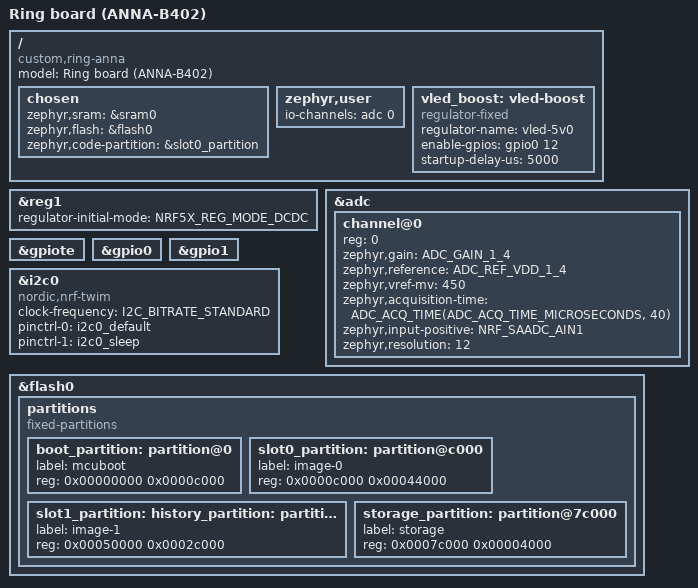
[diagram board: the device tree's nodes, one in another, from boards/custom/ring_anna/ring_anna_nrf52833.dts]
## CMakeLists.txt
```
cmake_minimum_required(VERSION 3.20.0)

find_package(Zephyr REQUIRED HINTS $ENV{ZEPHYR_BASE})
project(ring_ppg)

target_sources(app PRIVATE
	src/main.c
	src/maxm86161.c
	src/hr.c
	src/selftest.c
	src/ble.c
	src/imu.c
	src/wdt.c
	src/steps.c
	src/sleep.c
	src/calories.c
	src/profile.c
	src/hrv.c
	src/spo2.c
	src/history.c
	src/thermo.c
	src/spot.c
	src/ota.c
)

# ota.c includes img_mgmt.h, which pulls in MCUboot's bootutil headers.
# img_mgmt gets their include paths by linking this interface library;
# so does the app.
if(CONFIG_MCUBOOT_IMG_MANAGER)
	target_link_libraries(app PRIVATE MCUBOOT_BOOTUTIL)
endif()
```

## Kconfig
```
# Ring firmware application options.
#
# This file becomes KCONFIG_ROOT for the application (see Zephyr's
# cmake/modules/kconfig.cmake), so it MUST end by sourcing Kconfig.zephyr or
# no Zephyr symbol resolves at all.
#
# Everything bench-only lives here rather than as a #define inside a .c
# file. That is deliberate: the flags used to be scattered across main.c and
# imu.c, and "production" was produced by hand-editing main.c and keeping a
# main.c.bench copy alongside it. Two files that have to be edited in step
# is a bug waiting to happen, and the duplicate rotted immediately.
#
# Now both images come from one tree with no file edits:
#
#   .\build.ps1            production
#   .\build.ps1 -Bench     bench instrumentation

mainmenu "Ring firmware"

menu "Ring firmware"

config RING_BENCH
	bool "Bench instrumentation (NOT for anything worn or shipped)"
	help
	  Master switch for every bench-only instrument in this firmware.

	  These instruments perturb what they measure and defeat the power
	  model, which is fine on a desk with a debugger attached and wrong
	  everywhere else. Off by default so an ordinary build is shippable.

if RING_BENCH

config RING_BENCH_POWER_LED
	bool "Hold the green LED on as a power indicator"
	default y
	help
	  Holds MAXM86161 LED1 solid so "is the board actually running?" is
	  answerable by looking at it rather than by attaching a debugger.
	  Hours went into faults that turned out to be an unpowered board
	  presenting as a dead SWD link.

	  Costs real current and keeps the 5 V boost enabled permanently,
	  so the idle power model does not apply while this is set.

config RING_IMU_WAKE_DIAG
	bool "IMU wake-path diagnostics"
	default y
	help
	  Samples the INT1 pin before reading the latched wake source, which
	  separates "the IMU never fired" from "the IMU fired and the pin did
	  not move". This is what localised the cold joint on U4.

	  It reads latched registers and pulses INT1, so it perturbs the very
	  interrupt path the firmware depends on. Never leave it on outside
	  bring-up.

config RING_GSR_MONITOR
	bool "Live GSR monitor"
	default y
	help
	  Samples GSR in every state and holds GSR_PWR on continuously so the
	  front end stays settled and a meter can reach it.

	  Holding GSR_PWR on defeats duty cycling and keeps the analog front
	  end powered for as long as the board is.

endif # RING_BENCH

config RING_WATCHDOG
	bool "Hardware watchdog"
	default y
	select WATCHDOG
	help
	  Resets the SoC if the main loop stops feeding it. Without this a
	  wedged I2C bus or a hung loop is an unrecoverable brick that only a
	  power cycle clears -- and on a sealed ring, that means waiting for
	  the battery to die.

	  The nRF52833 watchdog CANNOT be stopped once started; only a
	  power-on reset clears it. It is therefore started last, after all
	  initialisation has succeeded.

config RING_WATCHDOG_TIMEOUT_MS
	int "Watchdog timeout (ms)"
	default 10000
	range 1000 100000
	depends on RING_WATCHDOG
	help
	  Must comfortably exceed the longest span between two
	  ring_wdt_feed() calls, because exceeding it reboots a board that
	  is merely slow.

	  THE AUDIT LIVES BESIDE THE FEED CALL IN main.c, and that is the
	  only copy. A duplicate of the numbers used to sit here and went
	  stale immediately: it counted only the k_msleep() delays, missed
	  that a stalled I2C bus costs 500 ms per transaction, and claimed
	  a margin that did not exist. Read main.c rather than trusting a
	  figure quoted here.

config RING_SLEEP_WEAR_CHECK
	bool "Corroborate sleep sessions with a PPG wear check"
	default y
	help
	  Opens a short PPG window every so often while a sleep session is
	  open, purely to read the DC level and answer "is this ring on a
	  hand?". Without it, stillness is the only input the sleep tracker
	  has and a ring left on a nightstand logs a full night -- confirmed
	  behaviour, not a hypothesis.

	  It costs LED current at night, but only where the answer is "no".
	  A worn ring never goes stale -- finding a finger during an ordinary
	  window refreshes the motion timeout -- so it is already measuring
	  every minute and its scheduled windows answer this for free: at
	  most one extra 6 s window per session, and usually none. A ring off
	  a finger DOES go stale three minutes in, and there the check adds
	  roughly 16 windows of 6 s, about 96 s of LED1 per night at ~15.4 mA
	  off the 5 V rail, against the ~12 s that night cost before.

	  That is ~0.41 mAh at 5 V, or ~0.65 mAh referred to a 3.7 V cell at
	  an assumed 85 % boost efficiency, before the AFE's own draw. NOBODY
	  HAS MEASURED THE BATTERY, so what fraction of a night that is
	  remains unknown. The arithmetic and the simulated window counts are
	  in STATUS.md section 5; the far larger pre-existing cost of the
	  duty cycle itself is R13 in the same file.

	  The verdict is reported, never enforced: a session that fails the
	  check is still reported as sleep, and the app decides what to do
	  with it.

	  Set this to n and no window is ever opened to ask the question, so
	  the power model is exactly what it was before this option existed.
	  Sessions then report RING_WEAR_UNKNOWN, except where a window
	  opened for some other reason -- an app-forced measurement, opcode
	  0x03 -- happens to land inside one. That reading is free and is
	  still recorded either way.

config RING_SLEEP_WEAR_CHECK_INTERVAL_MIN
	int "Minutes between sleep wear checks"
	default 30
	range 5 1440
	depends on RING_SLEEP_WEAR_CHECK
	help
	  How long to wait between wear checks within one sleep session. The
	  first check of a session is taken as soon as the session opens, so
	  a verdict of "not worn" -- which needs two negatives -- lands about
	  one interval after onset.

	  Cost scales linearly: halving this doubles the LED time per night.
	  Set it beyond a night's length (say 600) to get exactly one check
	  per session, which is the cheapest useful setting and cannot notice
	  a ring taken off at 2 am.

config RING_SLEEP_WEAR_CHECK_WINDOW_MS
	int "Length of a sleep wear-check window (ms)"
	default 6000
	range 4000 30000
	depends on RING_SLEEP_WEAR_CHECK
	help
	  How long the PPG runs for one wear check. This only has to settle
	  the DC tracker, not acquire a heart rate, so it is far shorter than
	  MEASURE_WINDOW_MS.

	  The floor is the ~4 s settling figure the measurement window is
	  sized around; the 6 s default is that plus margin. Nothing shorter
	  has been tried on hardware, because there is no hardware -- do not
	  lower the floor on the strength of the filter time constant alone.

config RING_HR_CONTINUOUS
	bool "Keep the PPG running continuously (heart-rate test builds only)"
	default n
	help
	  Opens a measurement window at boot and never closes it, so heart
	  rate is computed and notified over the standard Heart Rate Service
	  once a second for as long as the board is up. Nothing has to pair
	  or send an opcode: any HRS client that connects sees live BPM.

	  Exists to test the optical path and the beat detector against a
	  reference on a bench. It ignores the duty cycle, the no-finger
	  timeout and the stillness timeout, so green LED1 and the 5 V boost
	  run the whole time -- never ship it. Built with hr-test.conf into
	  build-hrtest, so it cannot be left where a production image is
	  expected.

config RING_PPG_ON_DEMAND
	bool "Measure only when the app asks -- no automatic windows"
	default n
	help
	  Drops the duty cycle: no scheduled window every minute, no window
	  on a motion wake. Green LED1 and the 5 V boost come on only when
	  the app asks -- PPG streaming (opcode 0x01), which holds a window
	  open for as long as it runs, or measure-now (opcode 0x03), which
	  opens one 25 s window. A connected app can do everything it could
	  before; the ring just never decides to measure on its own.

	  For demos and bench sessions where the ring is carried around all
	  day and should only light up when someone is watching. It also
	  means no heart rate unless an app is connected and asking, so it
	  is not a shipping configuration. Built by .\build.ps1 -Demo with
	  demo.conf, which also turns the sleep wear check off.

config RING_CHARGE_LED
	bool "Hold the red LED on for as long as the charger is attached"
	default n
	help
	  Without this, attaching a charger flashes LED3 red for 3 s and then
	  leaves the optics dark. With it, red stays on until the charger is
	  removed, and the ring then goes back to whatever it was doing --
	  in an HR test build, green heart-rate measurement.

	  It is not free: the indicator holds the 5 V boost up and averages
	  roughly 2 mA of LED current (~3 mA at the cell) against a 20 mA
	  charge current, so a charge takes on the order of 15 % longer.
	  Off by default for that reason; hr-test.conf turns it on.

config RING_MEASURE_PERIOD_S
	int "Seconds between automatic measurement windows"
	default 60
	range 15 3600
	help
	  Each window lights green LED1 for 25 s, and the LED plus the 5 V
	  boost are the dominant draw on this board. 60 s is 25 % duty;
	  daily.conf uses 600 s (2.5 %) so a ring worn all day lasts the
	  day. The app can still change it at runtime with opcode 0x04.

config RING_HISTORY_EPOCH_S
	int "Seconds summarised by each on-ring history record"
	default 300
	range 60 3600
	help
	  The ring writes one 32-byte summary to flash every epoch -- heart
	  rate (mean, min, max), RMSSD, spot readings, steps, temperature,
	  motion, hot flashes, battery and worn/charging/asleep/workout flags
	  -- whether or not a phone is connected, and the app downloads them
	  later (control opcode 0x0E). See src/history.h and
	  APP_INTEGRATION.md section 16.

	  The partition holds 5,504 records, so capacity is this times
	  5,504: 19 days at the default 300 s, 3.8 days at 60 s. Shorter
	  epochs also wear the flash faster, though even 60 s cycles each
	  page only about twice a week.

config RING_PPG_LED_PA
	int "Green LED drive code for heart-rate windows (0.12 mA per LSB)"
	default 255
	range 1 255
	help
	  0xFF (255) is ~30.6 mA, 0x80 (128) ~15.4 mA, in the 31 mA range.
	  Together with RING_PPG_AVG_LOG2 this sets the LED energy per
	  sample, which dominates the ring's power budget while it measures
	  (POWER.md): the MAXM86161 draws ~600 uA from VLED at 100 sps with
	  0xFF and one pulse a sample, and scales with both settings.

	  255 is what every test build ran since v0.6.2. prod.conf sets 128.
	  Opcode 0x10 overrides it at run time in test builds.

config RING_PPG_AVG_LOG2
	int "On-chip averaging for heart-rate windows: 2^n pulses a sample"
	default 2
	range 0 2
	help
	  0, 1, 2 = average 1, 2, 4 pulses; output stays 100 sps. Each step
	  doubles the LED energy. 2 (4x) is what every test build ran since
	  v0.6.2; prod.conf sets 1 (2x).

	  Why production is not at 4x: on 2026-10-08's 30 s recordings, the
	  cheapest setting (15 mA, no averaging) scored as well as 31 mA with
	  4x once the detector despikes -- at an eighth of the LED energy --
	  but 30 s per setting cannot separate them. Settle it with
	  tools/ppg_sweep.py --ab against a WHOOP.

config RING_IMU_LOW_POWER
	bool "Run the accelerometer in low-power mode at 60 Hz"
	default n
	help
	  The accelerometer runs all day -- wake-on-motion and the step
	  counter need it -- and every build so far ran it in high-performance
	  mode at 120 Hz: ~190 uA by the LSM6DSV datasheet, several mAh a day
	  on its own. Low-power mode with 4-sample averaging at 60 Hz is ~20
	  uA, with somewhat more noise -- a few mg, against the ~80-100 mg
	  swings that wake the ring and count a step.

	  NOT YET VERIFIED ON HARDWARE. The register value comes from ST's
	  LSM6DSV16BX driver, but nobody has checked that wake-on-motion still
	  fires and steps still count in this mode on the ring. Off in the test
	  builds; prod.conf turns it on, and the first prod flash must confirm
	  both (ROADMAP.md).

config RING_DIAG_OPCODES
	bool "Accept diagnostic control opcodes 0x10 (PPG tune) and 0x11 (TX power)"
	default y
	help
	  Lets tools/ppg_sweep.py change the PPG front end and the radio's
	  transmit power over BLE without a reflash. On for every test build,
	  as it was in v0.6.2.

	  Off in production (prod.conf): they are tuning instruments, not
	  settings, and 0x11 is suspected of one reboot (2026-10-08) that was
	  never cleared. With this off both opcodes are refused with ATT 0x13
	  like any unknown opcode.

config RING_GSR_STATUS
	bool "Sample GSR every 30 s for the status packet"
	default y
	help
	  Powers the GSR front end and waits its 800 ms settle every 30 s to
	  fill gsr_mv in the Status characteristic. On for every test build,
	  as it was in v0.6.2.

	  Off in production (prod.conf), for two reasons learned in testing:
	  the front end cannot resolve skin conductance on this board (gain
	  about 10x too low, noise larger than the signal), and the 800 ms
	  settle blocks the main loop, so the step counter misses a stride
	  every 30 s of walking. gsr_mv then reads -1 ("not measured"). The
	  raw GSR stream (opcode 0x08) still works for diagnostics.

config RING_ADV_SLOW_AFTER_S
	int "Seconds of fast advertising before slowing to ~1 s (0 = never)"
	default 0
	range 0 3600
	help
	  The ring advertises every 30-60 ms so a phone finds it at once. Kept
	  up all day while nothing is connected, that is roughly 20 radio
	  events a second, likely several mAh a day at +8 dBm -- a large share
	  of a battery this small. With this set, advertising
	  drops to 1-1.2 s once it has run fast for this long after boot or
	  a disconnect. A phone still finds the ring within about a second;
	  it just stops paying for instant discovery nobody is waiting on.

	  0 (the default) keeps the fast advertising every test build had.
	  prod.conf sets 30.

config RING_CONN_PARAM_MGMT
	bool "Ask the central for an idle or fast connection interval"
	default n
	help
	  Without this the ring keeps whatever interval the phone or PC
	  chose, typically 15-30 ms, for the whole connection. With it the
	  ring asks for ~100 ms with latency 4 while idle, waking about every
	  half second, and 15-30 ms while a raw stream or a history sync
	  needs the throughput. See ble_service() in ble.c.

	  Off by default, as every test build was. prod.conf turns it on.

config RING_HRS_OPEN
	bool "Leave the standard Heart Rate Service readable without pairing"
	default y
	depends on BT_HRS
	help
	  Heart rate is a biometric, and by default this firmware broadcasts
	  it over the standard Heart Rate Service (0x180D) with no encryption
	  required: anyone in range who connects can read it. That is a
	  deliberate trade, not an oversight.

	  Keep it y and any off-the-shelf HR app -- a watch face, a cycling
	  computer, a generic BLE HRM client -- pairs with nothing and just
	  works, which is the whole point of implementing the SIG service
	  instead of only the custom one. The cost is that resting heart rate
	  leaks to anybody within a few metres.

	  Set it to n and the HRS characteristics require an encrypted link,
	  so only a bonded phone can read heart rate. Generic clients that do
	  not pair will see the service, fail to subscribe, and show nothing.
	  The Ring Service status packet has always been encrypted and carries
	  hr_x10, so a first-party app loses nothing either way.

	  This does not touch the Battery Service, which stays open.

config RING_SPOT_NIGHT_MIN
	int "Minutes between night spot readings (0 = off)"
	default 0
	range 0 720
	help
	  A spot reading is a long green PPG window -- RING_SPOT_WINDOW_S --
	  taken for a clean resting heart rate and RMSSD rather than a quick
	  heart rate. Night readings start 15 min after sleep onset and
	  repeat at this interval while asleep. They are what the app's
	  burnout trend is built on. See src/spot.h.

	  Off by default, as every test build was. prod.conf sets 60. The
	  app can change it at run time (opcode 0x12, RAM only). 1-9 are
	  refused there, and raised to 10 here (spot_init()): back-to-back
	  readings would keep the LED on all night.

config RING_SPOT_DAY_MIN
	int "Minutes between daytime spot readings (0 = off)"
	default 0
	range 0 720
	help
	  Daytime spot readings: awake, worn, and the accelerometer still
	  for 3 minutes, at most once per this interval. The app's stress
	  readings come from these, against the night baseline.

	  Off by default. prod.conf sets 60.

config RING_SPOT_WINDOW_S
	int "Length of a spot reading, seconds"
	default 180
	range 60 600
	help
	  Long enough for the beat detector to prime (~10 s) and then
	  collect well over a hundred consecutive beats at a resting heart
	  rate; the reading's RMSSD is over all of them (hrv_session). Each reading at the default costs about seven
	  25 s heart-rate windows' worth of LED.

config RING_HOT_FLASH_MODE
	int "Hot-flash detection: 0 off, 1 while asleep, 2 always"
	default 0
	range 0 2
	help
	  Watches the ring temperature for the quick rise of a hot flash --
	  see src/thermo.h for the algorithm and its caveats. The
	  temperature itself is logged in every build regardless; this only
	  decides whether events are detected, counted, flagged in the
	  history and followed by a spot reading.

	  Off by default. prod.conf sets 1: night sweats are the case the
	  temperature can see cleanly, a still hand under a duvet. The app
	  can change it (opcode 0x13).

config RING_HOT_FLASH_RISE_C10
	int "Hot-flash onset threshold, tenths of a degree C"
	default 10
	range 3 50
	help
	  How far above its settled baseline the ring temperature has to
	  climb, three quarters of it within 10 minutes. 1.0 C is a
	  starting point, not a fit: the nRF die reads the finger through
	  the ring, attenuated, and nobody has worn this board through a
	  hot flash yet.

# Selecting a choice entry provokes a Kconfig warning, so steer the choice
# instead. This file is KCONFIG_ROOT and sources Kconfig.zephyr at the end,
# so this default is evaluated before the upstream one in
# subsys/bluetooth/services/Kconfig.hrs.
choice BT_HRS_DEFAULT_PERM
	default BT_HRS_DEFAULT_PERM_RW_ENCRYPT if BT_HRS && !RING_HRS_OPEN
endchoice

endmenu

source "Kconfig.zephyr"
```

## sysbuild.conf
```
# Sysbuild: MCUboot in front of the app, for over-the-air updates (OTA.md).
#
# Overwrite-only, because two full image slots do not fit beside the
# history log in 512 kB (see the partitions in the board DTS). That mode
# has no revert: MCUboot checks the update's signature and hash before it
# copies, so a damaged or foreign upload is refused and the old image
# keeps running, but a correctly signed image that is broken in itself
# stays installed. Try every release on an unsealed board first.
SB_CONFIG_BOOTLOADER_MCUBOOT=y
SB_CONFIG_MCUBOOT_MODE_OVERWRITE_ONLY=y

# The update is LZMA2-compressed so it fits the 176 kB secondary slot,
# which is the history partition.
SB_CONFIG_MCUBOOT_COMPRESSED_IMAGE_SUPPORT=y

# ECDSA P-256 with this project's own key, not MCUboot's published
# development key -- anyone holding that one could sign an image this
# ring would accept. keys/ is gitignored: keep a copy of the key
# somewhere safe, because without it no sealed ring can be updated again.
SB_CONFIG_BOOT_SIGNATURE_TYPE_ECDSA_P256=y
SB_CONFIG_BOOT_SIGNATURE_KEY_FILE="\${APP_DIR}/keys/ring-mcuboot-ecdsa-p256.pem"
```

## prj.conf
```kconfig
CONFIG_I2C=y
CONFIG_GPIO=y
CONFIG_REGULATOR=y
CONFIG_REGULATOR_FIXED=y

# There is no UART on this board -- SWD is the only wire out, so the console
# and the log backend both go over SEGGER RTT.
CONFIG_SERIAL=n
CONFIG_UART_CONSOLE=n
CONFIG_USE_SEGGER_RTT=y
CONFIG_RTT_CONSOLE=y
CONFIG_CONSOLE=y

CONFIG_LOG=y
CONFIG_LOG_BACKEND_RTT=y
CONFIG_LOG_BACKEND_UART=n
CONFIG_LOG_BUFFER_SIZE=4096

# The default 1 kB SEGGER RTT up-buffer overflows during boot and silently
# drops log lines -- the IMU init and wake readback landed in the gap. The
# backend drops rather than blocks, so this is invisible except as missing
# timestamps. 8 kB covers the whole boot sequence.
CONFIG_SEGGER_RTT_BUFFER_SIZE_UP=8192

CONFIG_MAIN_STACK_SIZE=2048

# GSR analog front end
CONFIG_ADC=y

# --- Bluetooth: standard Heart Rate Monitor peripheral ---
CONFIG_BT=y
CONFIG_BT_PERIPHERAL=y
CONFIG_BT_DEVICE_NAME="Ring PPG"
CONFIG_BT_DEVICE_APPEARANCE=833
CONFIG_BT_HRS=y
CONFIG_BT_BAS=y
CONFIG_BT_SMP=y
CONFIG_BT_MAX_CONN=1

# No 32.768 kHz crystal on this board, so the controller runs its sleep
# clock from the internal RC (CLOCK_CONTROL_NRF_K32SRC_RC in the board
# defconfig). BLE tolerates the lower accuracy; it just widens receive
# windows slightly and costs a little power.

# Larger ATT MTU so raw PPG streaming is not capped at 4 samples per packet
CONFIG_BT_L2CAP_TX_MTU=247
CONFIG_BT_BUF_ACL_RX_SIZE=251
CONFIG_BT_BUF_ACL_TX_SIZE=251
CONFIG_BT_CTLR_DATA_LENGTH_MAX=251
CONFIG_BT_ATT_PREPARE_COUNT=2
CONFIG_BT_GATT_DYNAMIC_DB=n

# --- Bluetooth: pairing, bonding, encryption --------------------------------
#
# The Ring Service carries biometrics and accepts control opcodes, so every
# one of its attributes now demands an encrypted link (see src/ble.c). The
# ring has no display and no keypad, so the association model is Just Works:
# encrypted, bonded, but no MITM protection. That is the best an IO-less
# peripheral can do, and it is a long way better than the open link this
# replaces.
#
# Bonds have to survive a reboot or every power cycle would force a re-pair,
# so they go through the settings subsystem into a flash partition. NVS is
# the backend: Zephyr 4.4 picks SETTINGS_ZMS if ZMS is on and SETTINGS_NVS
# otherwise, and ZMS targets the RRAM parts (nRF54L), not nRF52 flash.
#
# CONFIG_BT_SMP is already set above.
CONFIG_BT_SETTINGS=y
CONFIG_SETTINGS=y
CONFIG_FLASH=y
CONFIG_FLASH_MAP=y
CONFIG_NVS=y

# Let NVS rebuild a storage partition it cannot make sense of.
#
# nvs_init() walks every sector looking for one that is still open. If they
# all look closed -- which is what stale bytes from an older image, or a
# half-finished erase, present as -- it gives up with -EDEADLK unless this is
# set (subsys/kvss/nvs/nvs.c). -EDEADLK propagates out of settings_load(),
# and since v0.4.1 that is fatal to BLE, so a single garbage sector would
# cost the ring its radio with no way back except an erase over SWD.
#
# With this set NVS flattens the region and starts a fresh instance instead.
# That destroys whatever was there, which for this partition means the bonds
# -- and bonds that cannot be parsed are already lost. Erasing before the
# first flash (see release/README.md) avoids ever needing this; it exists so
# that forgetting to is recoverable in the field rather than on a bench.
CONFIG_NVS_INIT_BAD_MEMORY_REGION=y

# Honour zephyr,code-partition from the board DTS, so the linker knows the
# image must stop short of the settings partition. Without this the chosen
# node is inert and a big enough image would silently overlap the bonds.
CONFIG_USE_DT_CODE_PARTITION=y

# --- Device Information Service ---------------------------------------------
#
# So a phone can tell which firmware it is talking to without a debugger.
# The revision string is also logged at boot from ble_start().
CONFIG_BT_DIS=y
CONFIG_BT_DIS_FW_REV=y
CONFIG_BT_DIS_FW_REV_STR="0.9.0"
CONFIG_BT_DIS_MANUF_NAME_STR="Ring project"
CONFIG_BT_DIS_MODEL_NUMBER_STR="Ring ANNA-B402"

# --- survivability ---------------------------------------------------------
#
# A fatal error (bus fault, stack overflow, failed assert) used to spin
# forever in k_fatal_halt: a dead ring that only a power cycle cleared, and
# on a sealed board that means waiting for the battery to run down. Reboot
# instead. Zephyr's z_fatal_error() calls LOG_PANIC() first, so the fault
# dump is flushed synchronously over RTT before the reset lands.
CONFIG_RESET_ON_FATAL_ERROR=y
CONFIG_REBOOT=y

# Reset cause survives the reset and is read back at boot -- the only way to
# tell a watchdog reset from someone plugging in a charger. See main.c.
CONFIG_HWINFO=y

# Stack overflow is caught by the MPU guard, which the board defconfig
# already enables (CONFIG_ARM_MPU + CONFIG_HW_STACK_PROTECTION). With the
# MPU doing it, CONFIG_STACK_SENTINEL would only add a slower, weaker second
# check, so it is deliberately left off.

# --- radio power at run time ------------------------------------------------
#
# Lets control opcode 0x11 change the TX power of a live connection through
# the controller's vendor HCI command. Exists to answer one question with a
# sweep rather than a reflash: do the PPG glitches follow the radio? The
# default level is still whatever CONFIG_BT_CTLR_TX_PWR_* says.
CONFIG_BT_CTLR_TX_PWR_DYNAMIC_CONTROL=y

# --- over-the-air updates ---------------------------------------------------
#
# MCUboot sits in front of the app (sysbuild.conf) and the SMP server below
# takes a signed, compressed image over BLE into slot 1 -- which is the
# history partition, so src/ota.c stops the log while an upload runs. The
# phone side is Nordic's nRF Connect Device Manager library (or
# tools/ota_update.py). See OTA.md.
CONFIG_MCUMGR=y
CONFIG_ZCBOR=y
CONFIG_CRC=y
CONFIG_STREAM_FLASH=y
CONFIG_IMG_MANAGER=y
CONFIG_MCUBOOT_IMG_MANAGER=y

# The version MCUboot and the phone see in the image header. Keep it equal
# to CONFIG_BT_DIS_FW_REV_STR above.
CONFIG_MCUBOOT_IMGTOOL_SIGN_VERSION="0.9.0"

# LZMA2 dictionary the update is compressed with. Must equal MCUboot's, in
# sysbuild/mcuboot.conf, which has to hold it in RAM to decompress.
CONFIG_NRF_COMPRESS_LZMA_MAX_DICT_SIZE=65536

# Erase slot 1 a page at a time as the upload reaches it, not all 176 kB
# up front: one long erase blocks the SMP thread for ~4 s.
CONFIG_IMG_ERASE_PROGRESSIVELY=y

CONFIG_MCUMGR_GRP_IMG=y
CONFIG_MCUMGR_GRP_OS=y
# Lets the phone size its chunks to the buffers below.
CONFIG_MCUMGR_GRP_OS_MCUMGR_PARAMS=y

# Same rule as the Ring Service: nothing over SMP without an encrypted
# (bonded) link. Anyone in range could otherwise wipe the history by
# starting an upload, even though MCUboot would refuse to install it.
CONFIG_MCUMGR_TRANSPORT_BT=y
CONFIG_MCUMGR_TRANSPORT_BT_PERM_RW_ENCRYPT=y
CONFIG_MCUMGR_TRANSPORT_BT_REASSEMBLY=y
CONFIG_MCUMGR_TRANSPORT_NETBUF_SIZE=1024
CONFIG_MCUMGR_TRANSPORT_NETBUF_COUNT=4
CONFIG_MCUMGR_TRANSPORT_WORKQUEUE_STACK_SIZE=2048

# src/ota.c hears about upload start, progress and end through these.
CONFIG_MCUMGR_MGMT_NOTIFICATION_HOOKS=y
CONFIG_MCUMGR_GRP_IMG_STATUS_HOOKS=y
CONFIG_MCUMGR_GRP_IMG_UPLOAD_CHECK_HOOK=y
CONFIG_MCUMGR_SMP_COMMAND_STATUS_HOOKS=y
```

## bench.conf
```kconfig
# Bench instrumentation.
#
#   .\build.ps1 -Bench
#
# Turns on every diagnostic that is compiled out of a normal build. All of
# these perturb what they measure or defeat the power model, so this is for
# a board on a desk with a debugger attached and nothing else.
#
# What this changes:
#   - green LED1 held solid as a power indicator, 5 V boost never sleeps
#   - IMU wake diagnostics, which read latched registers and pulse INT1
#   - live GSR monitor, which holds GSR_PWR on continuously
#   - the full boot self-test suite (battery, IMU, GSR sweeps, pin probes)
#
# This reproduces the behaviour of the archived v0.1-bench green-LED image.

CONFIG_RING_BENCH=y
```

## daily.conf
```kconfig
# Daily-wear build: the ring measures on its own, lightly, and keeps a
# history in flash for the phone app to sync -- so the phone does not have
# to stay connected for anything to be recorded.
#
#   .\build.ps1 -Daily       -> build-daily\ring-fw\zephyr\zephyr.hex
#
# The difference from production is power and range, not features.

# One 25 s heart-rate window every 10 minutes (~4 % duty) instead of every
# minute (~42 %). Every window lands in the 5-minute history record it falls
# in, so roughly every other record carries a heart rate. The app can tighten
# this at runtime with opcode 0x04 while it is open.
CONFIG_RING_MEASURE_PERIOD_S=600

# Red held on while charging.
CONFIG_RING_CHARGE_LED=y

# +8 dBm: the antenna is untuned and a phone in a pocket is further away
# than a PC on a desk. See hr-test.conf.
CONFIG_BT_CTLR_TX_PWR_PLUS_8=y
```

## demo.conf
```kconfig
# Demo build: the ring stays dark and idle until the dashboard switches the
# green PPG on, so it lasts a day of being carried around and still shows
# live heart rate on cue. Not a shipping configuration -- see
# CONFIG_RING_PPG_ON_DEMAND in Kconfig.
#
#   .\build.ps1 -Demo        -> build-demo\ring-fw\zephyr\zephyr.hex
#
# Control it with tools/dashboard.py (the "Green PPG" button).

# No automatic measurement windows; only the app opens one.
CONFIG_RING_PPG_ON_DEMAND=y

# The sleep wear check opens short PPG windows on its own at night. Off, so
# nothing lights the LED except the app.
CONFIG_RING_SLEEP_WEAR_CHECK=n

# Red held on while charging.
CONFIG_RING_CHARGE_LED=y

# +8 dBm: the antenna is untuned, and a demo link that drops is worse than
# the extra radio current. See hr-test.conf.
CONFIG_BT_CTLR_TX_PWR_PLUS_8=y
```

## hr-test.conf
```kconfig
# Heart-rate test build: PPG runs continuously, live BPM over the standard
# Heart Rate Service, no pairing needed. Bench use only -- see
# CONFIG_RING_HR_CONTINUOUS in Kconfig.
#
#   .\build.ps1 -HrTest      -> build-hrtest\ring-fw\zephyr\zephyr.hex
#
# Read it with tools/live_hr.py, or any HRS app (nRF Toolbox -> HRM).

CONFIG_RING_HR_CONTINUOUS=y

# Red held on while charging, back to green measurement when unplugged.
CONFIG_RING_CHARGE_LED=y

# +8 dBm, the nRF52833's maximum, up from the 0 dBm default. The antenna is
# untuned and the ring measured ~16 dB below a WHOOP at the same spot, so
# the streaming link to a PC drops within seconds at 0 dBm. Costs radio
# current on every packet; production stays at 0 dBm until the antenna is
# tuned and the trade is measured.
CONFIG_BT_CTLR_TX_PWR_PLUS_8=y
```

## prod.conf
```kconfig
# Production build: what the v0.6 test campaign (2026-10-07 to 10-12)
# taught, applied. The plain `.\build.ps1` uses this, into build\.
#
# Everything the test builds have that production needs is already in the
# shared source: the on-ring history, the spectral heart-rate detector, the
# 31 mA / 4x-averaged PPG front end, 25 s windows, the inherited-watchdog
# fix, and the rhythm-gated step counter. This file only sets what differs.
#
# The test firmware itself is frozen in ../ring-fw-test-v0.6.2.

# The antenna is untuned and measured ~17 dB below a WHOOP (-79 dBm against
# -62 at the same spot); a Windows link dropped within seconds at -80 to
# -89 dBm. +8 dBm is the nRF52833's maximum. Until the antenna is retuned,
# a link that holds matters more than the radio current.
CONFIG_BT_CTLR_TX_PWR_PLUS_8=y

# One 25 s heart-rate window every 5 minutes (~8 % duty): one per history
# record. The default 60 s period with 25 s windows would be ~42 % duty,
# and the LED plus the 5 V boost dominate the power budget. An app can still
# tighten it while it is open (opcode 0x04).
CONFIG_RING_MEASURE_PERIOD_S=300

# Red held on while charging.
CONFIG_RING_CHARGE_LED=y

# No GSR sampling for the status packet: the front end cannot resolve skin
# conductance on this board, and its 800 ms settle stalled the step counter
# every 30 s. See CONFIG_RING_GSR_STATUS.
CONFIG_RING_GSR_STATUS=n

# No diagnostic opcodes (0x10 PPG tune, 0x11 TX power). 0x11 needs the
# controller's dynamic TX power command, so that goes too.
CONFIG_RING_DIAG_OPCODES=n
CONFIG_BT_CTLR_TX_PWR_DYNAMIC_CONTROL=n

# Advertise fast for 30 s after boot or a disconnect, then every ~1 s.
# Fast advertising all day is likely several mAh a day at +8 dBm.
CONFIG_RING_ADV_SLOW_AFTER_S=30

# Ask for a ~100 ms / latency-4 connection while idle, 15-30 ms while
# streaming or syncing history, instead of the central's 15-30 ms always.
CONFIG_RING_CONN_PARAM_MGMT=y

# PPG front end at a quarter of the test builds' LED energy: ~15 mA, 2x
# averaging, instead of ~31 mA, 4x. PROVISIONAL -- the 2026-10-08 sweep
# could not separate the settings; tools/ppg_sweep.py --ab decides. At 25 s
# every 300 s the test setting alone is ~7-8 mAh a day (POWER.md).
CONFIG_RING_PPG_LED_PA=128
CONFIG_RING_PPG_AVG_LOG2=1

# Accelerometer in low-power mode at 60 Hz (~20 uA) instead of
# high-performance at 120 Hz (~190 uA, all day). Must be verified on the
# first prod flash: wake-on-motion still fires, steps still count.
CONFIG_RING_IMU_LOW_POWER=y

# ble_service() owns the connection interval, so Zephyr's own automatic
# request (its preferred 30-50 ms, latency 0, 5 s after connecting) must
# not race it. The preferred parameters a central can read from the GAP
# service say the same as the idle request: 75-105 ms, latency 4, 4 s.
CONFIG_BT_GAP_AUTO_UPDATE_CONN_PARAMS=n
CONFIG_BT_PERIPHERAL_PREF_MIN_INT=60
CONFIG_BT_PERIPHERAL_PREF_MAX_INT=84
CONFIG_BT_PERIPHERAL_PREF_LATENCY=4
CONFIG_BT_PERIPHERAL_PREF_TIMEOUT=400

# Spot readings for the app's stress and burnout scores: a 3-minute green
# window every hour asleep and at most every hour awake and still. ~5 %
# extra LED duty at night, less by day. See src/spot.h.
CONFIG_RING_SPOT_NIGHT_MIN=60
CONFIG_RING_SPOT_DAY_MIN=60

# Hot-flash detection from the ring temperature, while asleep only.
# UNVALIDATED threshold; see src/thermo.h.
CONFIG_RING_HOT_FLASH_MODE=1
```

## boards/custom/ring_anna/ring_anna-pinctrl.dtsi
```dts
/*
 * Pin control for the ring board.
 *
 * Netlist -> ANNA-B402 pad -> nRF52833 port:
 *   SDA : U5.10 = GPIO_10 = P0.20
 *   SCL : U5.11 = GPIO_11 = P0.14
 *
 * SDA/SCL are pulled up externally to 1V8 by R2/R1, so no internal
 * bias is requested here.
 */

&pinctrl {
	i2c0_default: i2c0_default {
		group1 {
			psels = <NRF_PSEL(TWIM_SDA, 0, 20)>,
				<NRF_PSEL(TWIM_SCL, 0, 14)>;
		};
	};

	i2c0_sleep: i2c0_sleep {
		group1 {
			psels = <NRF_PSEL(TWIM_SDA, 0, 20)>,
				<NRF_PSEL(TWIM_SCL, 0, 14)>;
			low-power-enable;
		};
	};
};
```

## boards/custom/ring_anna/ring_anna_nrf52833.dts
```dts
/dts-v1/;
#include <nordic/nrf52833_qiaa.dtsi>
#include "ring_anna-pinctrl.dtsi"
#include <zephyr/dt-bindings/adc/adc.h>
#include <zephyr/dt-bindings/adc/nrf-saadc.h>

/ {
	model = "Ring board (ANNA-B402)";
	compatible = "custom,ring-anna";

	chosen {
		zephyr,sram = &sram0;
		zephyr,flash = &flash0;
		zephyr,code-partition = &slot0_partition;
	};

	zephyr,user {
		io-channels = <&adc 0>;
	};

	/*
	 * TPS61240 boost (U1). BOOST_EN = U5.15 = GPIO_15 = P0.12.
	 * Its 5V output feeds MAXM86161 VLED (U3.5). Nothing on the
	 * board turns this on for us, so the firmware must.
	 */
	vled_boost: vled-boost {
		compatible = "regulator-fixed";
		regulator-name = "vled-5v0";
		enable-gpios = <&gpio0 12 GPIO_ACTIVE_HIGH>;
		startup-delay-us = <5000>;
	};
};

/*
 * ANNA-B402 carries the DC/DC inductors inside the module, so the SoC
 * regulator can run in buck mode instead of LDO.
 */
&reg1 {
	regulator-initial-mode = <NRF5X_REG_MODE_DCDC>;
};

/*
 * GSR front end. U7 (OPA2333) drives GSR_ADC into P0.03 = AIN1.
 * GSR_PWR (P0.11) powers the divider; leave it off when not measuring.
 *
 * The node is channel@0, not channel@1. The channel index is just a SAADC
 * channel slot and is independent of the analog input; the input is chosen
 * by zephyr,input-positive below.
 *
 * This used to be channel@1. The move is a hypothesis, not a confirmed fix,
 * and it is worth being honest about that: adc_nrfx_saadc.c rejects a
 * channel_id only when it is >= SAADC_CH_NUM, and accepts channel 1 with any
 * input exactly as it accepts channel 0. Nothing in the driver requires
 * index 0.
 *
 * The missing zephyr,vref-mv below -- already fixed -- on its own explains
 * every 0 mV reading this project has ever recorded, because the conversion
 * multiplied by a vref of zero. So the most likely outcome of the A/B in
 * gsr_ain_scan() is that ch0 and ch1 read the same, meaning the index was
 * never the fault.
 *
 * The move is harmless either way and has been made; the bench log decides.
 * See HANDOFF.md section 5, "Cause 2". Moved 2026-09-17.
 */
&adc {
	status = "okay";
	#address-cells = <1>;
	#size-cells = <0>;

	channel@0 {
		reg = <0>;
		zephyr,gain = "ADC_GAIN_1_4";
		zephyr,reference = "ADC_REF_VDD_1_4";
		/*
		 * MANDATORY for any reference other than ADC_REF_INTERNAL.
		 * ADC_DT_SPEC_GET defaults vref_mv to 0 when this property is
		 * absent, and adc_raw_to_millivolts_dt() computes
		 * raw * vref_mv -- so every conversion returns 0 mV however
		 * good the sample is. That read as "GSR is dead" for weeks.
		 *
		 * Reference here is VDD/4 with VDD = 1.8 V, so 450 mV. Gain
		 * 1/4 is inverted by the conversion, giving full scale 1.8 V.
		 */
		zephyr,vref-mv = <450>;
		zephyr,acquisition-time = <ADC_ACQ_TIME(ADC_ACQ_TIME_MICROSECONDS, 40)>;
		zephyr,input-positive = <NRF_SAADC_AIN1>;
		zephyr,resolution = <12>;
	};
};

&gpiote {
	status = "okay";
};

&gpio0 {
	status = "okay";
};

&gpio1 {
	status = "okay";
};

/* MAXM86161 (U3) and LSM6DSV (U4) share this bus at 1V8. */
&i2c0 {
	compatible = "nordic,nrf-twim";
	status = "okay";
	/* 100 kHz rather than 400 kHz: more timing margin while bringing
	 * the board up. The MAXM86161 and LSM6DSV both support 400 kHz.
	 */
	clock-frequency = <I2C_BITRATE_STANDARD>;
	pinctrl-0 = <&i2c0_default>;
	pinctrl-1 = <&i2c0_sleep>;
	pinctrl-names = "default", "sleep";
};

/*
 * nrf52833_qiaa.dtsi gives flash0 as one undivided 512 kB region with no
 * partitions node at all, so there was nowhere for the settings subsystem
 * to put BLE bonds. Split it.
 *
 * 16 kB of storage is four erase pages; settings_nvs caps its sector count
 * at what the partition actually holds, so this gives NVS four sectors --
 * ample for a single bond's keys and CCC state.
 *
 * Since v0.9.0 the bottom of flash is MCUboot, and over-the-air updates
 * need somewhere to land. Two full image slots do not fit: the image is
 * ~245 kB with the SMP server, and 2 x 245 + bootloader + bonds leaves
 * nothing for the history log. So the update is LZMA2-compressed
 * (MCUboot overwrite-only mode, SB_CONFIG_MCUBOOT_COMPRESSED_IMAGE_SUPPORT)
 * and lands in the history partition, which doubles as slot 1. An update
 * therefore costs the history -- the app syncs first, src/ota.c stops the
 * log writing for the duration, and history_init() formats the region
 * again on the next boot. See OTA.md.
 *
 * zephyr,code-partition above is what makes this binding rather than
 * decorative: with CONFIG_USE_DT_CODE_PARTITION the linker is told the
 * image ends at 0x50000, so an image that grew into the history log or
 * the bonds would fail to link instead of quietly eating them at run time.
 *
 * NVS does NOT recover from stale bytes at 0x7c000 by itself. nvs_init()
 * returns -EDEADLK when every sector looks closed, and only rebuilds the
 * region if CONFIG_NVS_INIT_BAD_MEMORY_REGION is set -- which prj.conf
 * does, with the reasoning. Erase the part before the first flash anyway;
 * see release/README.md.
 */
&flash0 {
	partitions {
		compatible = "fixed-partitions";
		#address-cells = <1>;
		#size-cells = <1>;

		/* MCUboot, overwrite-only, with the LZMA2 decompressor. */
		boot_partition: partition@0 {
			label = "mcuboot";
			reg = <0x00000000 0x0000c000>;
		};

		/*
		 * 272 kB for the running image, ~245 kB as of v0.9.0. It
		 * starts with MCUboot's 512-byte image header.
		 */
		slot0_partition: partition@c000 {
			label = "image-0";
			reg = <0x0000c000 0x00044000>;
		};

		/*
		 * On-ring history (src/history.c): one 4 kB header page and
		 * 43 pages of 32-byte records, ~19 days at a 5-minute epoch.
		 * Also MCUboot's secondary slot: a compressed update is staged
		 * here, so it must stay at least as big as the compressed
		 * image (~150 kB). Unmoved since v0.6, so a v0.8 ring keeps
		 * its log across the reflash that adds the bootloader.
		 *
		 * MCUboot only looks inside this slot when the trailer at its
		 * end says an upgrade is pending (boot_validated_swap_type()),
		 * so the log is never mistaken for, or erased as, a bad image
		 * in a normal boot.
		 */
		slot1_partition: history_partition: partition@50000 {
			label = "image-1";
			reg = <0x00050000 0x0002c000>;
		};

		storage_partition: partition@7c000 {
			label = "storage";
			reg = <0x0007c000 0x00004000>;
		};
	};
};
```

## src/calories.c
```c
#include "calories.h"

#include <zephyr/sys/util.h>

#include <stddef.h>
#include <string.h>

#define DEFAULT_WEIGHT_KG_X10	700	/* 70.0 kg */
#define MIN_WEIGHT_KG_X10	200	/* 20.0 kg */
#define MAX_WEIGHT_KG_X10	2500	/* 250.0 kg */

/*
 * MET x10 by cadence upper bound, in steps per minute. 1 MET (x10 = 10) is
 * resting energy expenditure; the walking bands are the Ainsworth
 * Compendium's "walking, various speeds" entries mapped onto typical
 * cadence for each. See calories.h for why this is a rough estimate, not a
 * calibration.
 */
struct met_band {
	uint16_t max_cadence_spm;
	uint16_t met_x10;
};

static const struct met_band bands[] = {
	{  59,  10 },		/* below walking cadence: resting */
	{  79,  20 },		/* slow amble, ~2.0 mph */
	{  99,  28 },		/* easy walk, ~2.5-3.0 mph */
	{ 119,  35 },		/* brisk walk, ~3.5 mph */
	{ 139,  43 },		/* fast/power walk, ~4.0 mph */
	{ UINT16_MAX, 50 },	/* jogging cadence and above */
};

/* Anchors for the partial-minute blend below. MET_WALK_X10 is the band
 * PARTIAL_REF_SPM falls in, so the blend and the table agree exactly at a
 * full minute of ordinary walking.
 */
#define MET_REST_X10		10
#define MET_WALK_X10		28
#define PARTIAL_REF_SPM		99

/* Used by the heart-rate formula when the app has not sent an age. */
#define DEFAULT_AGE_YEARS	35
#define MIN_AGE_YEARS		10
#define MAX_AGE_YEARS		100

/*
 * MET x10 to fall back on for a workout minute with no usable heart rate.
 * Compendium of Physical Activities (2011) values for a middling effort:
 * running at 5 mph (8.3), stationary rowing at 100 W (7.0), general
 * bicycling (7.5). OTHER has no activity behind it and is a mid-range
 * guess, not a table entry.
 */
static const uint8_t workout_fallback_met_x10[] = {
	[WORKOUT_NONE]	= 10,
	[WORKOUT_RUN]	= 83,
	[WORKOUT_ROW]	= 70,
	[WORKOUT_CYCLE]	= 75,
	[WORKOUT_OTHER]	= 50,
};

static uint16_t weight_kg_x10 = DEFAULT_WEIGHT_KG_X10;
static uint8_t age_years;		/* 0 = not given */
static uint8_t sex = CAL_SEX_UNSPECIFIED;
static uint32_t total_kcal_x1000;

static struct calories_workout wk;
static uint32_t wk_hr_sum_x10;		/* for avg_hr_x10 */

void calories_init(void)
{
	weight_kg_x10 = DEFAULT_WEIGHT_KG_X10;
	age_years = 0;
	sex = CAL_SEX_UNSPECIFIED;
	total_kcal_x1000 = 0;
	memset(&wk, 0, sizeof(wk));
	wk_hr_sum_x10 = 0;
}

void calories_set_weight(uint16_t kg_x10)
{
	/*
	 * A malformed or wildly wrong write here poisons every estimate
	 * from this point on, so clamp to a physically plausible range
	 * rather than trusting the app.
	 */
	if (kg_x10 < MIN_WEIGHT_KG_X10) {
		kg_x10 = MIN_WEIGHT_KG_X10;
	} else if (kg_x10 > MAX_WEIGHT_KG_X10) {
		kg_x10 = MAX_WEIGHT_KG_X10;
	}

	weight_kg_x10 = kg_x10;
}

uint16_t calories_weight_kg_x10(void)
{
	return weight_kg_x10;
}

void calories_set_body(uint8_t age, uint8_t sex_code)
{
	if (age != 0) {
		age = CLAMP(age, MIN_AGE_YEARS, MAX_AGE_YEARS);
	}
	age_years = age;

	sex = (sex_code == CAL_SEX_FEMALE || sex_code == CAL_SEX_MALE)
	    ? sex_code : CAL_SEX_UNSPECIFIED;
}

uint8_t calories_age_years(void)
{
	return age_years;
}

uint8_t calories_sex(void)
{
	return sex;
}

static uint16_t met_x10_for_cadence(uint16_t cadence_spm)
{
	for (size_t i = 0; i < ARRAY_SIZE(bands); i++) {
		if (cadence_spm <= bands[i].max_cadence_spm) {
			return bands[i].met_x10;
		}
	}

	return bands[ARRAY_SIZE(bands) - 1].met_x10;
}

/*
 * kcal_x1000_per_min = met_x10 * weight_kg_x10 * 175 / 1000
 *
 * Derived from kcal/min = MET * weight_kg * 0.0175 (see calories.h)
 * with met_x10 = MET*10 and weight_kg_x10 = weight_kg*10:
 *   MET * weight_kg = met_x10 * weight_kg_x10 / 100
 *   kcal/min * 1000 = (met_x10 * weight_kg_x10 / 100) * 0.0175 * 1000
 *                    = met_x10 * weight_kg_x10 * 175 / 1000
 *
 * Largest possible product (met_x10=83, weight_kg_x10=2500) is
 * 36,312,500 before the final divide, well inside uint32_t.
 */
static uint32_t met_x10_minute_x1000(uint16_t met_x10)
{
	return ((uint32_t)met_x10 * weight_kg_x10 * 175U) / 1000U;
}

/* The step formula's price for one minute, kcal x1000. */
static uint32_t step_minute_x1000(uint32_t steps_this_minute)
{
	uint16_t spm = (steps_this_minute > UINT16_MAX)
		     ? UINT16_MAX : (uint16_t)steps_this_minute;
	uint16_t met_x10 = met_x10_for_cadence(spm);

	/*
	 * A minute that was only partly spent walking lands in a low band --
	 * 20 s at 110 spm is 37 steps, which the table calls resting even
	 * though a third of the minute was not. So also price the minute as
	 * a fraction of a walking minute and take whichever is higher:
	 *
	 *   blended MET = 1.0 + (steps / PARTIAL_REF_SPM) * (2.8 - 1.0)
	 *
	 * capped at the reference so a sustained fast walk keeps the higher
	 * band value rather than being pulled down to it. PARTIAL_REF_SPM is
	 * an ordinary walking cadence and MET_WALK_X10 its band, so a full
	 * minute at that cadence gives the same answer either way and the
	 * two agree at the seam.
	 */
	uint32_t partial_steps = MIN(steps_this_minute, (uint32_t)PARTIAL_REF_SPM);
	uint16_t blended_x10 = (uint16_t)(MET_REST_X10 +
		(partial_steps * (MET_WALK_X10 - MET_REST_X10)) / PARTIAL_REF_SPM);

	met_x10 = MAX(met_x10, blended_x10);

	return met_x10_minute_x1000(met_x10);
}

void calories_update_minute(uint32_t steps_this_minute)
{
	calories_update_minute_hr(steps_this_minute, 0);
}

/*
 * Keytel, in integers. Every coefficient is scaled by 1e5 and the inputs
 * arrive x10 (bpm x10, kg x10), so each product is kJ/min x1e5:
 *
 *   0.6309 kJ/min per bpm  = 63090 per bpm  = 6309 per bpm_x10
 *   0.1988 kJ/min per kg   = 19880 per kg   = 1988 per kg_x10
 *   0.2017 kJ/min per year = 20170 per year
 *
 * Largest male sum (250 bpm, 250 kg, 100 y) is about 22.8 million; x10
 * for the kcal conversion below is well inside int32_t.
 */
static int32_t keytel_male_kj_x1e5(int32_t hr_x10, int32_t w_x10, int32_t age)
{
	return -5509690 + 6309 * hr_x10 + 1988 * w_x10 + 20170 * age;
}

static int32_t keytel_female_kj_x1e5(int32_t hr_x10, int32_t w_x10,
				     int32_t age)
{
	return -2040220 + 4472 * hr_x10 - 1263 * w_x10 + 7400 * age;
}

uint32_t calories_keytel_x1000(uint16_t hr_x10)
{
	int32_t age = age_years ? age_years : DEFAULT_AGE_YEARS;
	int32_t kj;

	switch (sex) {
	case CAL_SEX_MALE:
		kj = keytel_male_kj_x1e5(hr_x10, weight_kg_x10, age);
		break;
	case CAL_SEX_FEMALE:
		kj = keytel_female_kj_x1e5(hr_x10, weight_kg_x10, age);
		break;
	default:
		/*
		 * No sex given: the mean of the two. It sits between the
		 * equations rather than picking one, which is the honest
		 * answer to not knowing, and costs at most half the spread.
		 */
		kj = (keytel_male_kj_x1e5(hr_x10, weight_kg_x10, age) +
		      keytel_female_kj_x1e5(hr_x10, weight_kg_x10, age)) / 2;
		break;
	}

	if (kj <= 0) {
		return 0;
	}

	/* kJ x1e5 -> kcal x1000: divide by 4.184 and by 100. */
	return (uint32_t)(((int64_t)kj * 10) / 4184);
}

static uint32_t workout_minute_x1000(uint32_t steps_this_minute,
				     uint16_t hr_x10)
{
	uint32_t by_steps = step_minute_x1000(steps_this_minute);

	if (hr_x10 >= WORKOUT_KEYTEL_MIN_HR_X10) {
		/*
		 * Floored at the step price: a heart rate that reads low
		 * while the wearer is visibly running is more likely the
		 * sensor slipping than the wearer coasting.
		 */
		uint32_t by_hr = MIN(calories_keytel_x1000(hr_x10),
				     (uint32_t)WORKOUT_MAX_KCAL_X1000);

		wk.hr_minutes++;
		wk_hr_sum_x10 += hr_x10;
		wk.avg_hr_x10 = (uint16_t)(wk_hr_sum_x10 / wk.hr_minutes);

		return MAX(by_hr, by_steps);
	}

	if (hr_x10 > 0) {
		wk.rest_minutes++;
		return by_steps;
	}

	wk.fallback_minutes++;

	uint8_t type = wk.type < ARRAY_SIZE(workout_fallback_met_x10)
		     ? wk.type : WORKOUT_OTHER;

	return MAX(met_x10_minute_x1000(workout_fallback_met_x10[type]),
		   by_steps);
}

void calories_update_minute_hr(uint32_t steps_this_minute, uint16_t hr_x10)
{
	if (!wk.active) {
		total_kcal_x1000 += step_minute_x1000(steps_this_minute);
		return;
	}

	uint32_t kcal = workout_minute_x1000(steps_this_minute, hr_x10);

	if (wk.minutes < UINT16_MAX) {
		wk.minutes++;
	}
	wk.kcal_x1000 += kcal;
	total_kcal_x1000 += kcal;
}

void calories_workout_start(uint8_t type)
{
	if (type == WORKOUT_NONE) {
		calories_workout_stop();
		return;
	}

	if (type >= ARRAY_SIZE(workout_fallback_met_x10)) {
		type = WORKOUT_OTHER;
	}

	if (!wk.active) {
		memset(&wk, 0, sizeof(wk));
		wk_hr_sum_x10 = 0;
		wk.active = true;
	}

	wk.type = type;
}

void calories_workout_stop(void)
{
	wk.active = false;
}

bool calories_workout_active(void)
{
	return wk.active;
}

void calories_workout_get(struct calories_workout *out)
{
	*out = wk;
}

uint32_t calories_total_x1000(void)
{
	return total_kcal_x1000;
}

void calories_reset(void)
{
	total_kcal_x1000 = 0;
}
```
